VERSION ""
CM_ "BYD Song PLUS DM-i 2023. Derived from byd_atto3.dbc: every message the port
uses validates on this car (checksum 100%), except 0x1F0 which carries four 12-bit
wheel speeds here instead of one clean speed. Fitted from this car own recording.";

NS_ :

BS_:

BU_: EPS ESP_ECU BCM VCU MPC_CAM ADAS_ECU MCU BSD

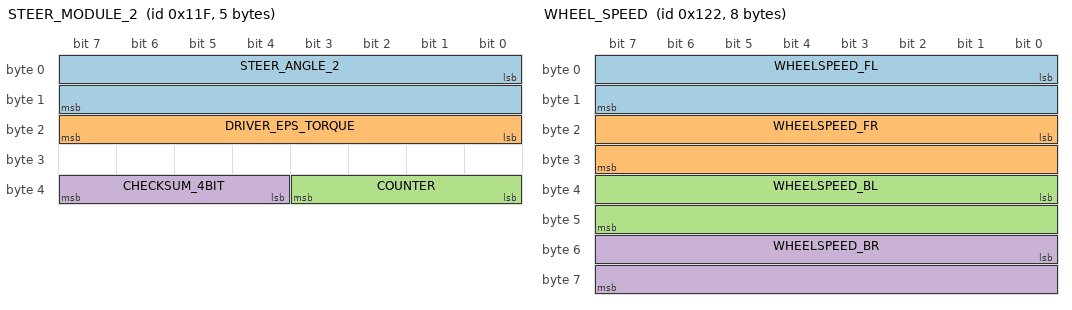
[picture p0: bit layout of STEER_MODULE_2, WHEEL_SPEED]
BO_ 287 STEER_MODULE_2: 5 EPS
 SG_ STEER_ANGLE_2 : 0|16@1- (0.1,0) [-780|780] "deg" MCU,ADAS_ECU
 SG_ DRIVER_EPS_TORQUE : 16|8@1+ (1,0) [0|255] "" MCU,ADAS_ECU
 SG_ COUNTER : 35|4@0+ (1,0) [0|15] "" MCU
 SG_ CHECKSUM_4BIT : 39|4@0+ (1,0) [0|15] "" MCU

BO_ 290 WHEEL_SPEED: 8 ESP_ECU
 SG_ WHEELSPEED_FL : 0|16@1+ (0.1,0) [0|6553.5] "kph" MCU,ADAS_ECU
 SG_ WHEELSPEED_FR : 16|16@1+ (0.1,0) [0|6553.5] "kph" MCU,ADAS_ECU
 SG_ WHEELSPEED_BL : 32|16@1+ (0.1,0) [0|6553.5] "kph" MCU,ADAS_ECU
 SG_ WHEELSPEED_BR : 48|16@1+ (0.1,0) [0|6553.5] "kph" MCU,ADAS_ECU

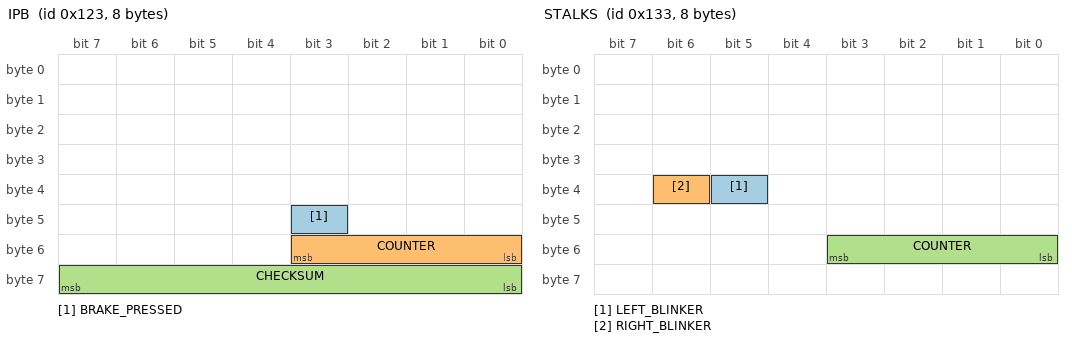
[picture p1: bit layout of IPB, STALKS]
BO_ 291 IPB: 8 IPB
 SG_ BRAKE_PRESSED : 43|1@1+ (1,0) [0|1] "" MCU
 SG_ COUNTER : 48|4@1+ (1,0) [0|15] "" MCU
 SG_ CHECKSUM : 56|8@1+ (1,0) [0|255] "" MCU

BO_ 307 STALKS: 8 BCM
 SG_ LEFT_BLINKER : 37|1@0+ (1,0) [0|1] "" MCU
 SG_ RIGHT_BLINKER : 38|1@0+ (1,0) [0|1] "" MCU
 SG_ COUNTER : 48|4@1+ (1,0) [0|15] "" MCU

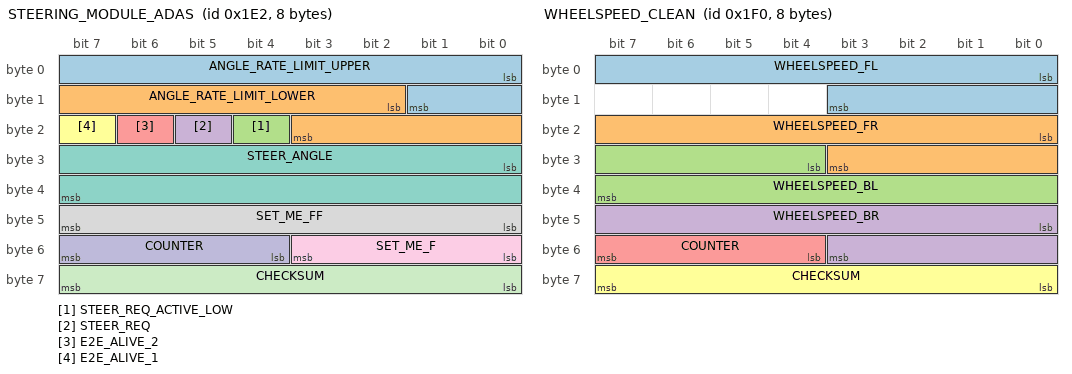
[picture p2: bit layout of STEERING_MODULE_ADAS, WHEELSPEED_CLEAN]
BO_ 482 STEERING_MODULE_ADAS: 8 ADAS_ECU
 SG_ ANGLE_RATE_LIMIT_UPPER : 0|10@1- (1,0) [-512|511] "" EPS
 SG_ ANGLE_RATE_LIMIT_LOWER : 10|10@1- (1,0) [-512|511] "" EPS
 SG_ STEER_REQ_ACTIVE_LOW : 20|1@0+ (1,0) [0|1] "" EPS
 SG_ STEER_REQ : 21|1@0+ (1,0) [0|1] "" EPS
 SG_ E2E_ALIVE_2 : 22|1@0+ (1,0) [0|1] "" EPS
 SG_ E2E_ALIVE_1 : 23|1@0+ (1,0) [0|1] "" EPS
 SG_ STEER_ANGLE : 24|16@1- (0.1,0) [-3276.8|3276.7] "deg" EPS
 SG_ SET_ME_FF : 47|8@0+ (1,0) [0|255] "" EPS
 SG_ SET_ME_F : 48|4@1+ (1,0) [0|15] "" EPS
 SG_ COUNTER : 55|4@0+ (1,0) [0|15] "" EPS
 SG_ CHECKSUM : 56|8@1+ (1,0) [0|255] "" EPS

BO_ 496 WHEELSPEED_CLEAN: 8 ESP_ECU
 SG_ WHEELSPEED_FL : 0|12@1+ (0.0725,0) [0|296.9] "kph" MCU
 SG_ WHEELSPEED_FR : 16|12@1+ (0.0725,0) [0|296.9] "kph" MCU
 SG_ WHEELSPEED_BL : 28|12@1+ (0.0725,0) [0|296.9] "kph" MCU
 SG_ WHEELSPEED_BR : 40|12@1+ (0.0725,0) [0|296.9] "kph" MCU
 SG_ COUNTER : 55|4@0+ (1,0) [0|15] "" MCU
 SG_ CHECKSUM : 56|8@1+ (1,0) [0|255] "" MCU
BO_ 508 STEERING_TORQUE: 8 EPS
 SG_ LKS_PREPARED : 0|1@1+ (1,0) [0|1] "" MCU,ADAS_ECU
 SG_ CRUISE_ACTIVATED : 1|1@1+ (1,0) [0|1] "" MCU,ADAS_ECU
 SG_ LKA_STATE : 0|2@1+ (1,0) [0|3] "" MCU,ADAS_ECU
 SG_ TORQUE_FAILED : 2|1@1+ (1,0) [0|1] "" MCU,ADAS_ECU
 SG_ DRIVER_TORQUE : 4|12@1- (0.1,0) [-204.8|204.7] "Nm" MCU,ADAS_ECU
 SG_ TARGET_ANGLE : 16|16@1- (0.1,0) [-3276.8|3276.7] "deg" MCU,ADAS_ECU
 SG_ MAIN_TORQUE : 32|12@1- (1,0) [-2048|2047] "" MCU,ADAS_ECU
 SG_ HANDS_ON_WHEEL_WARN : 45|1@1+ (1,0) [0|1] "" MCU,ADAS_ECU
 SG_ TORQUE_TEMP_FAILED : 46|2@1+ (1,0) [0|3] "" MCU,ADAS_ECU
 SG_ LKA_ABORT_CODE : 48|4@1+ (1,0) [0|15] "" MCU,ADAS_ECU
 SG_ COUNTER : 52|4@1+ (1,0) [0|15] "" MCU
 SG_ CHECKSUM : 56|8@1+ (1,0) [0|255] "" MCU

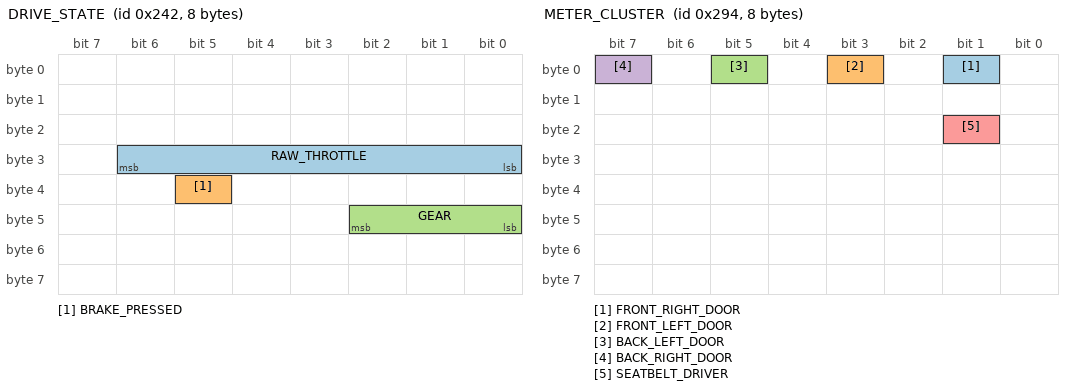
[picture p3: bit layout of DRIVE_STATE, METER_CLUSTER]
BO_ 578 DRIVE_STATE: 8 VCU
 SG_ RAW_THROTTLE : 30|7@0+ (1,0) [0|127] "" MCU
 SG_ BRAKE_PRESSED : 37|1@0+ (1,0) [0|1] "" MCU,ADAS_ECU
 SG_ GEAR : 40|3@1+ (1,0) [0|7] "" MCU

BO_ 660 METER_CLUSTER: 8 BCM
 SG_ FRONT_RIGHT_DOOR : 1|1@1+ (1,0) [0|1] "" MCU
 SG_ FRONT_LEFT_DOOR : 3|1@0+ (1,0) [0|1] "" MCU
 SG_ BACK_LEFT_DOOR : 5|1@1+ (1,0) [0|1] "" MCU
 SG_ BACK_RIGHT_DOOR : 7|1@0+ (1,0) [0|1] "" MCU
 SG_ SEATBELT_DRIVER : 17|1@0+ (1,0) [0|1] "" MCU

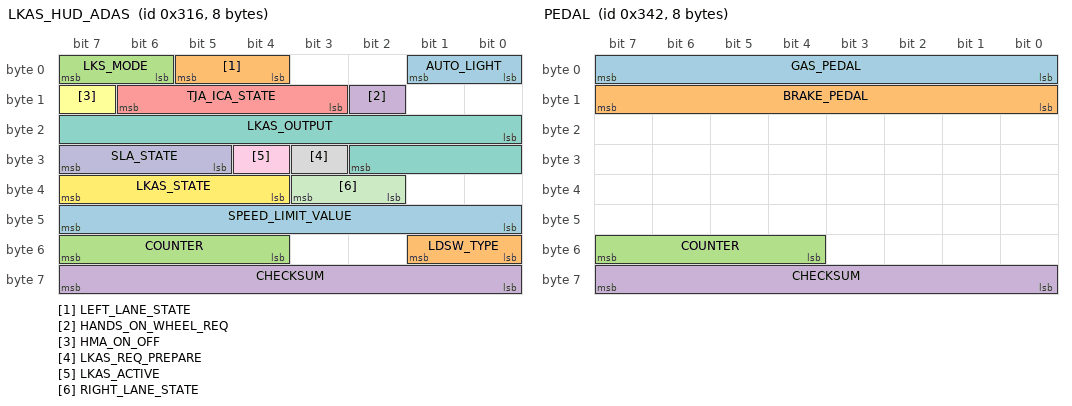
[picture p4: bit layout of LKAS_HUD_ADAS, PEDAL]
BO_ 790 LKAS_HUD_ADAS: 8 MPC_CAM
 SG_ AUTO_LIGHT : 1|2@0+ (1,0) [0|3] "" XXX
 SG_ LEFT_LANE_STATE : 4|2@1+ (1,0) [0|3] "" MCU
 SG_ LKS_MODE : 6|2@1+ (1,0) [0|3] "" MCU
 SG_ HANDS_ON_WHEEL_REQ : 10|1@1+ (1,0) [0|1] "" MCU
 SG_ TJA_ICA_STATE : 11|4@1+ (1,0) [0|15] "" MCU
 SG_ HMA_ON_OFF : 15|1@0+ (1,0) [0|1] "" MCU
 SG_ LKAS_OUTPUT : 16|11@1- (1,0) [-1024|1023] "" MCU
 SG_ LKAS_REQ_PREPARE : 27|1@1+ (1,0) [0|1] "" MCU
 SG_ LKAS_ACTIVE : 28|1@1+ (1,0) [0|1] "" MCU
 SG_ SLA_STATE : 29|3@1+ (1,0) [0|7] "" MCU
 SG_ RIGHT_LANE_STATE : 34|2@1+ (1,0) [0|3] "" MCU
 SG_ LKAS_STATE : 36|4@1+ (1,0) [0|15] "" MCU
 SG_ SPEED_LIMIT_VALUE : 40|8@1+ (5,-5) [-5|1270] "kph" MCU
 SG_ LDSW_TYPE : 49|2@0+ (1,0) [0|3] "" MCU
 SG_ COUNTER : 52|4@1+ (1,0) [0|15] "" MCU
 SG_ CHECKSUM : 56|8@1+ (1,0) [0|255] "" MCU

BO_ 813 ACC_HUD_ADAS: 8 ADAS_ECU
 SG_ ACC_ENGAGED_STATE : 10|2@1+ (1,0) [0|3] "" MCU
 SG_ SET_SPEED : 0|8@1+ (0.5,0) [0|127.5] "kph" MCU
 SG_ HAS_LEAD : 9|1@1+ (1,0) [0|1] "" MCU
 SG_ LEAD_DISTANCE : 13|3@1+ (1,0) [0|7] "" MCU
 SG_ SET_DISTANCE : 12|3@0+ (1,0) [0|7] "" MCU
 SG_ ACC_STATE : 19|3@1+ (1,0) [0|7] "" MCU
 SG_ ACC_ON2 : 20|1@0+ (1,0) [0|1] "" MCU
 SG_ ACC_ON1 : 22|1@0+ (1,0) [0|1] "" MCU
 SG_ WARNING_BIT_16 : 16|1@1+ (1,0) [0|1] "" MCU
 SG_ WARNING_BIT_17 : 17|1@1+ (1,0) [0|1] "" MCU
 SG_ WARNING_BIT_23 : 23|1@1+ (1,0) [0|1] "" MCU
 SG_ SET_ME_XFF : 47|8@0+ (1,0) [0|255] "" MCU
 SG_ ACC_STATE_CODE : 44|4@1+ (1,0) [0|15] "" MCU
 SG_ COUNTER : 48|4@1+ (1,0) [0|15] "" MCU
 SG_ SET_ME_XF : 55|4@0+ (1,0) [0|15] "" MCU
 SG_ CHECKSUM : 56|8@1+ (1,0) [0|255] "" MCU

BO_ 814 ACC_CMD: 8 ADAS_ECU
 SG_ ACC_AVAILABLE : 47|1@1+ (1,0) [0|1] "" MCU
 SG_ ACCEL_CMD : 0|8@1+ (1,-100) [-100|155] "" MCU
 SG_ ACC_ON_1 : 9|1@0+ (1,0) [0|1] "" MCU
 SG_ SET_ME_25_1 : 10|6@1+ (1,0) [0|63] "" MCU
 SG_ ACC_ON_2 : 17|1@0+ (1,0) [0|1] "" MCU
 SG_ SET_ME_25_2 : 18|6@1+ (1,0) [0|63] "" MCU
 SG_ DECEL_FACTOR : 24|4@1+ (1,0) [0|15] "" MCU
 SG_ SET_ME_X8 : 31|4@0+ (1,0) [0|15] "" MCU
 SG_ ACCEL_FACTOR : 32|4@1+ (1,0) [0|15] "" MCU
 SG_ CMD_REQ_ACTIVE_LOW : 36|1@0+ (1,0) [0|1] "" MCU
 SG_ SET_ME_1 : 38|1@0+ (1,0) [0|1] "" MCU
 SG_ STANDSTILL_RESUME : 39|1@0+ (1,0) [0|1] "" MCU
 SG_ STANDSTILL_STATE : 40|1@0+ (1,0) [0|1] "" MCU
 SG_ ACC_REQ_NOT_STANDSTILL : 43|1@0+ (1,0) [0|1] "" MCU
 SG_ ACC_CONTROLLABLE_AND_ON : 44|1@0+ (1,0) [0|1] "" MCU
 SG_ ACC_OVERRIDE_OR_STANDSTILL : 45|1@0+ (1,0) [0|1] "" MCU
 SG_ STOCK_BYTES_1_4 : 8|32@1+ (1,0) [0|4294967295] "" MCU
 SG_ STOCK_BYTE_5 : 40|8@1+ (1,0) [0|255] "" MCU
 SG_ COUNTER : 48|4@1+ (1,0) [0|15] "" MCU
 SG_ SET_ME_XF : 55|4@0+ (1,0) [0|15] "" MCU
 SG_ CHECKSUM : 56|8@1+ (1,0) [0|255] "" MCU

BO_ 834 PEDAL: 8 VCU
 SG_ GAS_PEDAL : 0|8@1+ (0.01,0) [0|2.55] "" MCU
 SG_ BRAKE_PEDAL : 8|8@1+ (0.01,0) [0|2.55] "" MCU
 SG_ COUNTER : 55|4@0+ (1,0) [0|15] "" MCU
 SG_ CHECKSUM : 56|8@1+ (1,0) [0|255] "" MCU

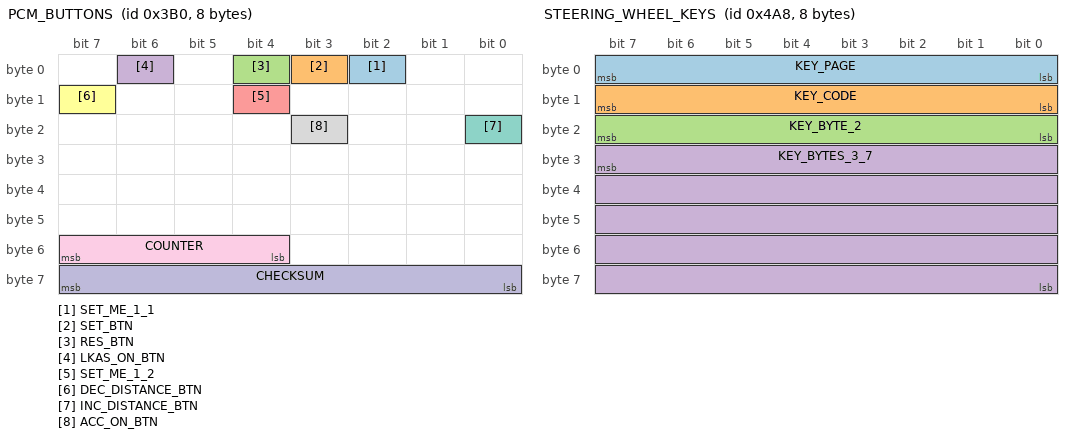
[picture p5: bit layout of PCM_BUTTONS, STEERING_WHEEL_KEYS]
BO_ 944 PCM_BUTTONS: 8 MCU
 SG_ SET_ME_1_1 : 2|1@0+ (1,0) [0|1] "" MCU
 SG_ SET_BTN : 3|1@0+ (1,0) [0|1] "" MCU
 SG_ RES_BTN : 4|1@0+ (1,0) [0|1] "" MCU
 SG_ LKAS_ON_BTN : 6|1@0+ (1,0) [0|1] "" MCU
 SG_ SET_ME_1_2 : 12|1@0+ (1,0) [0|1] "" MCU
 SG_ DEC_DISTANCE_BTN : 15|1@0+ (1,0) [0|1] "" MCU
 SG_ INC_DISTANCE_BTN : 16|1@0+ (1,0) [0|1] "" MCU
 SG_ ACC_ON_BTN : 19|1@0+ (1,0) [0|1] "" MCU
 SG_ COUNTER : 55|4@0+ (1,0) [0|15] "" MCU
 SG_ CHECKSUM : 63|8@0+ (1,0) [0|255] "" MCU

BO_ 1192 STEERING_WHEEL_KEYS: 8 XXX
 SG_ KEY_PAGE : 7|8@0+ (1,0) [0|255] "" XXX
 SG_ KEY_CODE : 15|8@0+ (1,0) [0|255] "" XXX
 SG_ KEY_BYTE_2 : 23|8@0+ (1,0) [0|255] "" XXX
 SG_ KEY_BYTES_3_7 : 31|40@0+ (1,0) [0|1099511627775] "" XXX

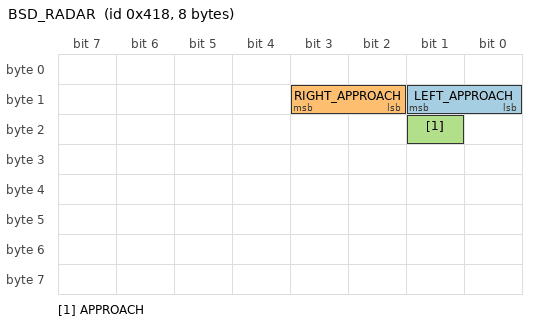
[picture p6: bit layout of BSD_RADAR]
BO_ 1048 BSD_RADAR: 8 BSD
 SG_ LEFT_APPROACH : 9|2@0+ (1,0) [0|3] "" MCU,ADAS_ECU
 SG_ RIGHT_APPROACH : 11|2@0+ (1,0) [0|3] "" MCU,ADAS_ECU
 SG_ APPROACH : 17|1@0+ (1,0) [0|1] "" MCU,ADAS_ECU

CM_ BO_ 287 "EPS steering wheel angle + driver torque. Validated: angle range plausible, DRIVER_EPS_TORQUE stays near 0 when hands-off.";
CM_ BO_ 290 "Per-wheel speed from ESP (FL/FR/BL/BR). Scale 0.1 kph/bit. Use WHEELSPEED_CLEAN (0x1F0) for the aggregated filtered value openpilot consumes.";
CM_ BO_ 307 "Turn signal / stalk info. Validated: LEFT_BLINKER and RIGHT_BLINKER transition 0->1 during lane change events.";
CM_ BO_ 482 "Lateral steering command sent by MPC camera/ADAS ECU to EPS. Blocked by panda on bus 2; panda injects its own on bus 0.";
CM_ SG_ 482 ANGLE_RATE_LIMIT_UPPER "Song PLUS: 500 while STEER_REQ is set and 300 while it is not, moving 16 per frame between the two in every recorded frame of the stack that steered this car. ANGLE_RATE_LIMIT_LOWER is its negative. With that ramp the EPS stopped steering 29-42 ms after STEER_REQ was dropped (18 times); sent 300 at once it went on for 250 ms (once).";
CM_ BO_ 496 "Wheel speed (cleaned average). Validated: 0-127 km/h matching driving speed.";
CM_ BO_ 508 "Column steering torque from EPS.";
CM_ SG_ 508 LKA_STATE "Song PLUS: what the EPS is doing with the lane-keeping command (0x1E2). LKS_PREPARED and CRUISE_ACTIVATED are its two bits. 0 = off: what it shows while the stock camera is the sender (its lane keeping is off on this car) and until it has accepted the device as the sender, 0.2 s after the relay closed with the car running and 10 s after it at a cold start. 1 = ready, 2 = steering to the commanded angle, 3 = aborted. It went 1 -> 2 within 46 ms of STEER_REQ in all 20 recorded requests and back to 1 within 0.26 s of the request being dropped. 3 was seen once: the driver held the wheel against the command, the EPS motor torque sat at its limit (499) for 0.68 s, then the state became 3, the motor torque went to 0 and LKA_ABORT_CODE to 10. It stayed that way with or without STEER_REQ, parked, for at least ten minutes, and was back to 1 after the car had been switched off and on.";
CM_ SG_ 508 LKA_ABORT_CODE "0 in every frame except while LKA_STATE is 3, where it read 10.";
CM_ SG_ 508 TARGET_ANGLE "Song PLUS: equals the measured steering angle (p99 difference 0.1 deg); it is not an echo of the commanded angle.";
CM_ BO_ 578 "Drivetrain state: gear, brake pressed, raw throttle.";
CM_ BO_ 660 "Body/meter cluster: doors + seatbelt.";
CM_ BO_ 790 "LKAS HUD ADAS message from camera. Blocked by panda on bus 2; panda re-injects.";
CM_ BO_ 813 "ACC HUD ADAS message (cruise set speed, distance, ACC state).";
CM_ SG_ 813 ACC_STATE_CODE "The stock ACC's own state, high nibble of byte 5 (the low nibble is 0). Measured on the Song PLUS: 2 standby, 3 controlling, 5 driver overriding with the gas pedal (the ACC stays on), 4 exiting (seen after the ACC key was pressed while the ACC was braking: it keeps braking until the driver brakes), 7 holding the car at standstill (seen once: ACC switched on while stopped; a brake press did not end it, the ACC key did), 1 unavailable (brake held, and for a moment after a brake cancel). Overlaps SET_ME_XFF, which is not a constant on this car.";
CM_ SG_ 813 ACC_ENGAGED_STATE "Same bits as SET_DISTANCE: the follow-distance setting, shown only while the ACC is on (0 when off). It changed 2->1 0.23 s after DEC_DISTANCE_BTN and 1->2 0.21 s after INC_DISTANCE_BTN. Non-zero means the ACC is on, including while it is exiting; use ACC_STATE_CODE to tell.";
CM_ SG_ 813 WARNING_BIT_17 "Called FCW in the DBC of the stack this car came with; what the instrument cluster shows for it is not known. Set once in all recordings: route 00000280 segment 64, 2026-10-22 07:16:43.92 UTC, 200 frames (3.99 s), at about 92 km/h with the driver already braking and the ACC in standby; ACC_CMD carried no request, 0x32F did not change and the car slowed by 0.9 m/s2 at most (migration-audit/longitudinal-l0-20261114/RESULT.txt, section 6). byd.h lets openpilot replace no ACC_CMD while this bit, bit 16 or bit 23 was set in the last two seconds.";
CM_ SG_ 813 HAS_LEAD "Set while the stock ACC's radar shows something ahead. Not only cars: on a closed course with no other car it was set 38 of 79 s. On the highway (route 0000026f, 699 s in which openpilot saw a lead within a 4 s time headway) it had been clear for 2 s in 4.3 of those seconds (0.6%), LEAD_DISTANCE as well. byd.h raises no request while it or LEAD_DISTANCE was non-zero in the last two seconds (migration-audit/longitudinal-l6-20261114).";
CM_ SG_ 813 LEAD_DISTANCE "How far away what HAS_LEAD reports is, in bars (0-4 seen); 0 when there is nothing. See HAS_LEAD.";
CM_ SG_ 813 WARNING_BIT_16 "Called AEB in the DBC of the stack this car came with. 0 in every recorded frame (541,652). See WARNING_BIT_17.";
CM_ SG_ 813 WARNING_BIT_23 "Called TOO_CLOSE in the DBC of the stack this car came with. 0 in every recorded frame (541,652). See WARNING_BIT_17.";
CM_ BO_ 814 "ACC acceleration command from the ADAS ECU, 50 Hz on bus 2. The panda forwards every frame to the car, except the one whose place a frame from openpilot has taken (byd.h, only with a longitudinal level in the safety param).";
CM_ SG_ 814 ACCEL_CMD "The request in counts of 0.05 m/s2 (the DBC of the stack this car came with: raw 100 is zero). Measured on the Song PLUS: the stock controller's own requests against the acceleration of the wheel speed, 29 s between -1.05 and +0.60 m/s2, gave r 0.96 and a slope of 0.89 at a lag of 0.30 s. Raw 0 (-100 here) is what the stock ACC sends while it holds the car at standstill. No data below -1.3 or above +1.2 m/s2.";
CM_ SG_ 814 STOCK_BYTES_1_4 "Bytes 1-4 as one number: the comfort band, the jerk limits and bits 31 and 39 as the stock controller sent them. Overlaps the signals above on purpose. For copying a stock frame byte for byte; when packing, give this and STOCK_BYTE_5 and none of the signals they overlap.";
CM_ SG_ 814 STOCK_BYTE_5 "Byte 5 as one number, see STOCK_BYTES_1_4. While the stock ACC is controlling it is 0xD8 in 99.8% of frames, 0xE8 while the driver overrides with the gas pedal, 0xD0 in standby, 0x48 when unavailable, 0x20 while exiting and 0xF0 (with bit 39 set) while holding at standstill.";
CM_ BO_ 834 "Gas/brake pedal percentages.";
CM_ BO_ 944 "Steering-wheel cruise control buttons.";
CM_ BO_ 1192 "Steering-wheel keys (360 view, custom, phone). Sent only while a key is down: every 100 ms, then one frame with KEY_CODE 0 at the release. Measured 2026-11-15 (route 00000032): KEY_PAGE always 1, KEY_BYTE_2 0x80, KEY_BYTES_3_7 0.";
CM_ SG_ 1192 KEY_CODE "0 released, 0x15 360-view key, 0x25 custom key short press, 0x26 custom key held, 0x0C phone key.";
CM_ SG_ 944 ACC_ON_BTN "Song PLUS: the ACC on/off key. A press reads as a 150-250 ms pulse. From standby it turns the ACC on 0.19-0.20 s later (2 presses). With the ACC engaged it turns it off: either 0.19-0.27 s later, straight to standby (10 presses), or only 1.7-1.8 s later and then to EXITING (3 presses; in one of them three more presses in between changed nothing). What decides between the two is not known.";
CM_ SG_ 944 LKAS_ON_BTN "Song PLUS: also turns the ACC on (40 ms later). Pressing it with the ACC on does nothing.";
VAL_ 508 TORQUE_TEMP_FAILED 1 "TooLarge" 2 "TooFast" 3 "Both";
VAL_ 508 LKA_STATE 0 "OFF" 1 "READY" 2 "ACTIVE" 3 "ABORTED";
VAL_ 578 GEAR 4 "D" 2 "R" 3 "N" 1 "P";
VAL_ 790 AUTO_LIGHT 1 "OFF" 2 "ON";
VAL_ 790 LEFT_LANE_STATE 0 "OFF" 1 "GREEN" 2 "ORANGE";
VAL_ 790 LKS_MODE 0 "OFF" 1 "DIVERGE" 2 "KEEPING" 3 "ALL";
VAL_ 790 TJA_ICA_STATE 0 "OFF" 1 "PASSIVE" 2 "ACTIVE1" 3 "ACTIVE2" 4 "FAULT";
VAL_ 790 SLA_STATE 0 "OFF" 1 "FUSION_MODE" 2 "VISION_MODE" 3 "NV_ONLY_MODE" 4 "DEFECT";
VAL_ 790 RIGHT_LANE_STATE 0 "OFF" 1 "GREEN" 2 "ORANGE";
VAL_ 790 LKAS_STATE 2 "ACTIVE" 1 "OFF";
VAL_ 790 LDSW_TYPE 0 "VIBRATE" 1 "SOUND" 2 "ALL";
VAL_ 813 SET_DISTANCE 4 "4bar" 3 "3bar" 2 "2bar" 1 "1bar";
VAL_ 813 ACC_STATE_CODE 1 "UNAVAILABLE" 2 "STANDBY" 3 "ACTIVE" 4 "EXITING" 5 "DRIVER_OVERRIDE" 7 "STANDSTILL_HOLD";
VAL_ 813 ACC_STATE 0 "OFF" 2 "ACC_ON" 3 "ACC_ACTIVE" 5 "FORCE_ACCEL" 7 "ERROR";
